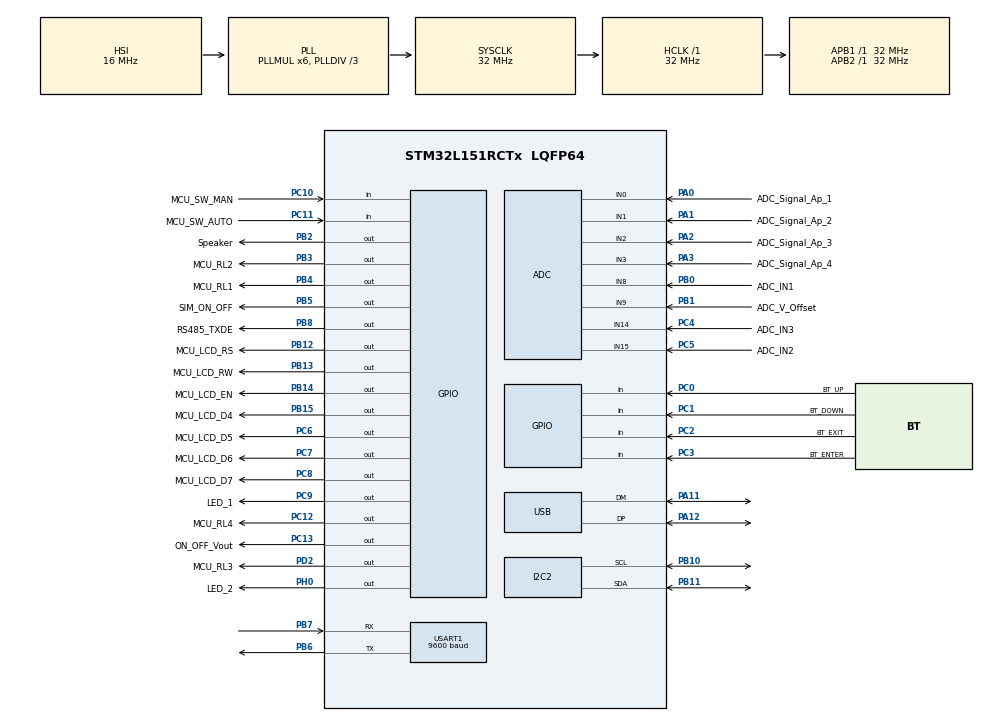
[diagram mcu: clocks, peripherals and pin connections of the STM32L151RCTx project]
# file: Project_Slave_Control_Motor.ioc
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ADC.Channel-0\#ChannelRegularConversion=ADC_CHANNEL_VREFINT
ADC.Channel-1\#ChannelRegularConversion=ADC_CHANNEL_0
ADC.Channel-2\#ChannelRegularConversion=ADC_CHANNEL_1
ADC.Channel-3\#ChannelRegularConversion=ADC_CHANNEL_2
ADC.Channel-4\#ChannelRegularConversion=ADC_CHANNEL_3
ADC.Channel-5\#ChannelRegularConversion=ADC_CHANNEL_14
ADC.Channel-6\#ChannelRegularConversion=ADC_CHANNEL_15
ADC.Channel-7\#ChannelRegularConversion=ADC_CHANNEL_8
ADC.Channel-8\#ChannelRegularConversion=ADC_CHANNEL_9
ADC.ContinuousConvMode=ENABLE
ADC.DMAContinuousRequests=ENABLE
ADC.NbrOfConversion=9
ADC.NbrOfConversionFlag=1
ADC.Rank-0\#ChannelRegularConversion=1
ADC.Rank-1\#ChannelRegularConversion=2
ADC.Rank-2\#ChannelRegularConversion=3
ADC.Rank-3\#ChannelRegularConversion=4
ADC.Rank-4\#ChannelRegularConversion=5
ADC.Rank-5\#ChannelRegularConversion=6
ADC.Rank-6\#ChannelRegularConversion=7
ADC.Rank-7\#ChannelRegularConversion=8
ADC.Rank-8\#ChannelRegularConversion=9
ADC.SamplingTime-0\#ChannelRegularConversion=ADC_SAMPLETIME_48CYCLES
ADC.SamplingTime-1\#ChannelRegularConversion=ADC_SAMPLETIME_48CYCLES
ADC.SamplingTime-2\#ChannelRegularConversion=ADC_SAMPLETIME_48CYCLES
ADC.SamplingTime-3\#ChannelRegularConversion=ADC_SAMPLETIME_48CYCLES
ADC.SamplingTime-4\#ChannelRegularConversion=ADC_SAMPLETIME_48CYCLES
ADC.SamplingTime-5\#ChannelRegularConversion=ADC_SAMPLETIME_48CYCLES
ADC.SamplingTime-6\#ChannelRegularConversion=ADC_SAMPLETIME_48CYCLES
ADC.SamplingTime-7\#ChannelRegularConversion=ADC_SAMPLETIME_48CYCLES
ADC.SamplingTime-8\#ChannelRegularConversion=ADC_SAMPLETIME_48CYCLES
ADC.ScanConvMode=ADC_SCAN_ENABLE
Dma.ADC.1.Direction=DMA_PERIPH_TO_MEMORY
Dma.ADC.1.Instance=DMA1_Channel1
Dma.ADC.1.MemDataAlignment=DMA_MDATAALIGN_HALFWORD
Dma.ADC.1.MemInc=DMA_MINC_ENABLE
Dma.ADC.1.Mode=DMA_CIRCULAR
Dma.ADC.1.PeriphDataAlignment=DMA_PDATAALIGN_HALFWORD
Dma.ADC.1.PeriphInc=DMA_PINC_DISABLE
Dma.ADC.1.Priority=DMA_PRIORITY_LOW
Dma.Request0=USART1_RX
Dma.Request1=ADC
Dma.USART1_RX.0.Direction=DMA_PERIPH_TO_MEMORY
Dma.USART1_RX.0.Instance=DMA1_Channel5
Dma.USART1_RX.0.MemDataAlignment=DMA_MDATAALIGN_BYTE
Dma.USART1_RX.0.MemInc=DMA_MINC_ENABLE
Dma.USART1_RX.0.Mode=DMA_CIRCULAR
Dma.USART1_RX.0.PeriphDataAlignment=DMA_PDATAALIGN_BYTE
Dma.USART1_RX.0.PeriphInc=DMA_PINC_DISABLE
Dma.USART1_RX.0.Priority=DMA_PRIORITY_LOW
IWDG.Prescaler=IWDG_PRESCALER_256
IWDG.Reload=2167
Mcu.Family=STM32L1
Mcu.Name=STM32L151RCTx
Mcu.Package=LQFP64
NVIC.DMA1_Channel1_IRQn=true\:0\:0\:false\:false\:true\:false\:true\:true
NVIC.DMA1_Channel5_IRQn=true\:0\:0\:false\:false\:true\:false\:true\:true
NVIC.PriorityGroup=NVIC_PRIORITYGROUP_4
NVIC.RTC_Alarm_IRQn=true\:0\:0\:false\:false\:true\:true\:true\:true
NVIC.TIM2_IRQn=true\:0\:0\:false\:false\:true\:true\:true\:true
NVIC.USART1_IRQn=true\:0\:0\:false\:false\:true\:true\:true\:true
NVIC.USB_LP_IRQn=true\:0\:0\:false\:false\:true\:true\:true\:true
PA0-WKUP1.GPIO_Label=ADC_Signal_Ap_1
PA0-WKUP1.Mode=IN0
PA0-WKUP1.Signal=ADC_IN0
PA1.GPIO_Label=ADC_Signal_Ap_2
PA1.Mode=IN1
PA1.Signal=ADC_IN1
PA11.Mode=Device
PA11.Signal=USB_DM
PA12.Mode=Device
PA12.Signal=USB_DP
PA13.Mode=Serial_Wire
PA13.Signal=SYS_JTMS-SWDIO
PA14.Mode=Serial_Wire
PA14.Signal=SYS_JTCK-SWCLK
PA2.GPIO_Label=ADC_Signal_Ap_3
PA2.Mode=IN2
PA2.Signal=ADC_IN2
PA3.GPIO_Label=ADC_Signal_Ap_4
PA3.Mode=IN3
PA3.Signal=ADC_IN3
PB0.GPIO_Label=ADC_IN1
PB0.Mode=IN8
PB0.Signal=ADC_IN8
PB1.GPIO_Label=ADC_V_Offset
PB1.Mode=IN9
PB1.Signal=ADC_IN9
PB10.Mode=I2C
PB10.Signal=I2C2_SCL
PB11.Mode=I2C
PB11.Signal=I2C2_SDA
PB12.GPIO_Label=MCU_LCD_RS
PB12.Signal=GPIO_Output
PB13.GPIO_Label=MCU_LCD_RW
PB13.Signal=GPIO_Output
PB14.GPIO_Label=MCU_LCD_EN
PB14.Signal=GPIO_Output
PB15.GPIO_Label=MCU_LCD_D4
PB15.Signal=GPIO_Output
PB2.GPIO_Label=Speaker
PB2.Signal=GPIO_Output
PB3.GPIO_Label=MCU_RL2
PB3.Signal=GPIO_Output
PB4.GPIO_Label=MCU_RL1
PB4.Signal=GPIO_Output
PB5.GPIO_Label=SIM_ON_OFF
PB5.Signal=GPIO_Output
PB6.Mode=Asynchronous
PB6.Signal=USART1_TX
PB7.Mode=Asynchronous
PB7.Signal=USART1_RX
PB8.GPIO_Label=RS485_TXDE
PB8.Signal=GPIO_Output
PC0.GPIO_Label=BT_UP
PC0.GPIO_PuPd=GPIO_PULLUP
PC0.Signal=GPIO_Input
PC1.GPIO_Label=BT_DOWN
PC1.GPIO_PuPd=GPIO_PULLUP
PC1.Signal=GPIO_Input
PC10.GPIO_Label=MCU_SW_MAN
PC10.GPIO_PuPd=GPIO_PULLUP
PC10.Signal=GPIO_Input
PC11.GPIO_Label=MCU_SW_AUTO
PC11.GPIO_PuPd=GPIO_PULLUP
PC11.Signal=GPIO_Input
PC12.GPIO_Label=MCU_RL4
PC12.Signal=GPIO_Output
PC13-WKUP2.GPIO_Label=ON_OFF_Vout
PC13-WKUP2.Signal=GPIO_Output
PC14-OSC32_IN.Mode=LSE-External-Oscillator
PC14-OSC32_IN.Signal=RCC_OSC32_IN
PC15-OSC32_OUT.Mode=LSE-External-Oscillator
PC15-OSC32_OUT.Signal=RCC_OSC32_OUT
PC2.GPIO_Label=BT_EXIT
PC2.GPIO_PuPd=GPIO_PULLUP
PC2.Signal=GPIO_Input
PC3.GPIO_Label=BT_ENTER
PC3.Signal=GPIO_Input
PC4.GPIO_Label=ADC_IN3
PC4.Mode=IN14
PC4.Signal=ADC_IN14
PC5.GPIO_Label=ADC_IN2
PC5.Mode=IN15
PC5.Signal=ADC_IN15
PC6.GPIO_Label=MCU_LCD_D5
PC6.Signal=GPIO_Output
PC7.GPIO_Label=MCU_LCD_D6
PC7.Signal=GPIO_Output
PC8.GPIO_Label=MCU_LCD_D7
PC8.Signal=GPIO_Output
PC9.GPIO_Label=LED_1
PC9.Signal=GPIO_Output
PD2.GPIO_Label=MCU_RL3
PD2.Signal=GPIO_Output
PH0-OSC_IN.GPIO_Label=LED_2
PH0-OSC_IN.Signal=GPIO_Output
ProjectManager.HeapSize=0x200
ProjectManager.StackSize=0x400
ProjectManager.TargetToolchain=EWARM V8.32
RCC.48MHZClocksFreq_Value=48000000
RCC.AHBFreq_Value=32000000
RCC.APB1Freq_Value=32000000
RCC.APB1TimFreq_Value=32000000
RCC.APB2Freq_Value=32000000
RCC.APB2TimFreq_Value=32000000
RCC.HCLKFreq_Value=32000000
RCC.HSE_VALUE=24000000
RCC.HSI_VALUE=16000000
RCC.MSI_VALUE=2097000
RCC.PLLDIV=RCC_PLL_DIV3
RCC.PLLMUL=RCC_PLL_MUL6
RCC.PLLSource=RCC_PLLSOURCE_HSI
RCC.PLLSourceVirtualString=RCC_PLLSOURCE_HSI
RCC.RTCClockSelection=RCC_RTCCLKSOURCE_LSE
RCC.RTCClockSelectionVirtual=RCC_RTCCLKSOURCE_LSE
RCC.SYSCLKFreq_VALUE=32000000
RCC.SYSCLKSource=RCC_SYSCLKSOURCE_PLLCLK
RCC.VCOOutputFreq_Value=96000000
RTC.Alarm-Alarm\ A=RTC_ALARM_A
RTC.Format=RTC_FORMAT_BIN
TIM2.Period=3200
USART1.BaudRate=9600
USART1.VirtualMode=VM_ASYNC
USB_DEVICE.CLASS_NAME_FS=CDC
USB_DEVICE.VirtualMode=Cdc
USB_DEVICE.VirtualModeFS=Cdc_FS
VP_ADC_Vref_Input.Mode=IN-Vrefint
VP_IWDG_VS_IWDG.Mode=IWDG_Activate
VP_RTC_VS_RTC_Activate.Mode=RTC_Enabled
VP_RTC_VS_RTC_Alarm_A_Intern.Mode=Alarm A
VP_RTC_VS_RTC_Calendar.Mode=RTC_Calendar
VP_TIM2_VS_ClockSourceINT.Mode=Internal
VP_USB_DEVICE_VS_USB_DEVICE_CDC_FS.Mode=CDC_FS
board=custom

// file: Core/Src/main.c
/* USER CODE BEGIN Header */
/**
  ******************************************************************************
  * @file           : main.c
  * @brief          : Main program body
  ******************************************************************************
  * @attention
  *
  * Copyright (c) 2024 STMicroelectronics.
  * All rights reserved.
  *
  * This software is licensed under terms that can be found in the LICENSE file
  * in the root directory of this software component.
  * If no LICENSE file comes with this software, it is provided AS-IS.
  *
  ******************************************************************************
  */
/* USER CODE END Header */
#include "main.h"
#include "adc.h"
#include "dma.h"
#include "i2c.h"
#include "iwdg.h"
#include "rtc.h"
#include "tim.h"
#include "usart.h"
#include "usb_device.h"
#include "gpio.h"

/* USER CODE BEGIN Includes */
#include "user_app_comm.h"
/* USER CODE END Includes */

void SystemClock_Config(void);

int main(void)
{

  /* MCU Configuration--------------------------------------------------------*/

  /* Reset of all peripherals, Initializes the Flash interface and the Systick. */
  HAL_Init();

  /* Configure the system clock */
  SystemClock_Config();

  /* Initialize all configured peripherals */
  MX_GPIO_Init();
  MX_DMA_Init();
  MX_ADC_Init();
  MX_I2C2_Init();
  MX_USART1_UART_Init();
  MX_USB_DEVICE_Init();
  MX_RTC_Init();
  MX_TIM2_Init();
  MX_IWDG_Init();
  /* USER CODE BEGIN 2 */
  Main_Task();
  /* USER CODE END 2 */

  /* Infinite loop */
  while (1)
  {

  }
}

void SystemClock_Config(void)
{
  RCC_OscInitTypeDef RCC_OscInitStruct = {0};
  RCC_ClkInitTypeDef RCC_ClkInitStruct = {0};
  RCC_PeriphCLKInitTypeDef PeriphClkInit = {0};

  /** Configure the main internal regulator output voltage
  */
  __HAL_PWR_VOLTAGESCALING_CONFIG(PWR_REGULATOR_VOLTAGE_SCALE1);

  /** Initializes the RCC Oscillators according to the specified parameters
  * in the RCC_OscInitTypeDef structure.
  */
  RCC_OscInitStruct.OscillatorType = RCC_OSCILLATORTYPE_HSI|RCC_OSCILLATORTYPE_LSI
                              |RCC_OSCILLATORTYPE_LSE;
  RCC_OscInitStruct.LSEState = RCC_LSE_ON;
  RCC_OscInitStruct.HSIState = RCC_HSI_ON;
  RCC_OscInitStruct.HSICalibrationValue = RCC_HSICALIBRATION_DEFAULT;
  RCC_OscInitStruct.LSIState = RCC_LSI_ON;
  RCC_OscInitStruct.PLL.PLLState = RCC_PLL_ON;
  RCC_OscInitStruct.PLL.PLLSource = RCC_PLLSOURCE_HSI;
  RCC_OscInitStruct.PLL.PLLMUL = RCC_PLL_MUL6;
  RCC_OscInitStruct.PLL.PLLDIV = RCC_PLL_DIV3;
  if (HAL_RCC_OscConfig(&RCC_OscInitStruct) != HAL_OK)
  {
    Error_Handler();
  }

  /** Initializes the CPU, AHB and APB buses clocks
  */
  RCC_ClkInitStruct.ClockType = RCC_CLOCKTYPE_HCLK|RCC_CLOCKTYPE_SYSCLK
                              |RCC_CLOCKTYPE_PCLK1|RCC_CLOCKTYPE_PCLK2;
  RCC_ClkInitStruct.SYSCLKSource = RCC_SYSCLKSOURCE_PLLCLK;
  RCC_ClkInitStruct.AHBCLKDivider = RCC_SYSCLK_DIV1;
  RCC_ClkInitStruct.APB1CLKDivider = RCC_HCLK_DIV1;
  RCC_ClkInitStruct.APB2CLKDivider = RCC_HCLK_DIV1;

  if (HAL_RCC_ClockConfig(&RCC_ClkInitStruct, FLASH_LATENCY_1) != HAL_OK)
  {
    Error_Handler();
  }
  PeriphClkInit.PeriphClockSelection = RCC_PERIPHCLK_RTC;
  PeriphClkInit.RTCClockSelection = RCC_RTCCLKSOURCE_LSE;
  if (HAL_RCCEx_PeriphCLKConfig(&PeriphClkInit) != HAL_OK)
  {
    Error_Handler();
  }
}

void Error_Handler(void)
{
  __disable_irq();
  while (1)
  {
  }
}
